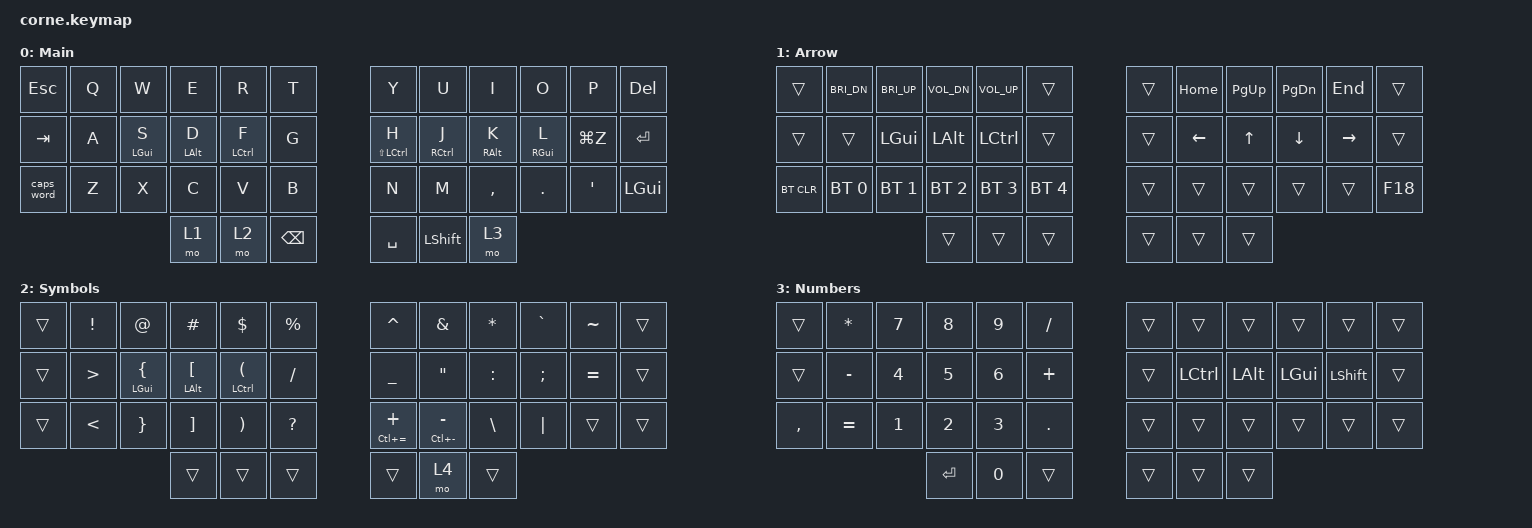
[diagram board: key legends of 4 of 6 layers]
/*
 * Copyright (c) 2020 The ZMK Contributors
 *
 * SPDX-License-Identifier: MIT
 */

#include <behaviors.dtsi>
#include <dt-bindings/zmk/keys.h>
#include <dt-bindings/zmk/bt.h>
#include <dt-bindings/zmk/pointing.h>

// Key positions on the 6-column Corne:
//    0  1  2  3  4  5      6  7  8  9 10 11
//   12 13 14 15 16 17     18 19 20 21 22 23
//   24 25 26 27 28 29     30 31 32 33 34 35
//            36 37 38     39 40 41
#define LEFT_KEYS   0 1 2 3 4 5 12 13 14 15 16 17 24 25 26 27 28 29
#define RIGHT_KEYS  6 7 8 9 10 11 18 19 20 21 22 23 30 31 32 33 34 35
#define THUMB_KEYS  36 37 38 39 40 41

// Fn/Mouse layer, used twice: layer 4 (held with both middle thumbs) and
// layer 5 (the same keys, locked on). Lock Layer = &tog 5: pressing it while
// holding the thumbs locks the layer; pressing it again unlocks.
// Drag Scroll and Navigator CPI +/- belong to the Voyager trackball, so they are empty here.
#define FN_MOUSE_BINDINGS \
   &kp F1  &kp F2  &kp F3         &kp F4     &kp F5     &kp F6    &trans  &msc SCRL_LEFT &msc SCRL_UP  &msc SCRL_DOWN &msc SCRL_RIGHT &trans \
   &trans  &trans  &none          &mkp LCLK  &mkp RCLK  &trans    &trans  &mmv MOVE_LEFT &mmv MOVE_UP  &mmv MOVE_DOWN &mmv MOVE_RIGHT &trans \
   &kp F7  &kp F8  &kp F9         &kp F10    &kp F11    &kp F12   &trans  &tog 5         &none         &none          &trans          &trans \
                   &trans         &trans     &trans               &trans  &trans         &trans

/ {
        behaviors {
                // Home row mods: tap for the letter, hold for the modifier.
                // A hold only counts when the next key is on the other hand or a
                // thumb, so fast typing on one hand doesn't fire modifiers by accident.
                hml: home_row_mod_left {
                        compatible = "zmk,behavior-hold-tap";
                        #binding-cells = <2>;
                        flavor = "balanced";
                        tapping-term-ms = <280>;
                        quick-tap-ms = <175>;
                        require-prior-idle-ms = <150>;
                        bindings = <&kp>, <&kp>;
                        hold-trigger-key-positions = <RIGHT_KEYS THUMB_KEYS>;
                        hold-trigger-on-release;
                };
                hmr: home_row_mod_right {
                        compatible = "zmk,behavior-hold-tap";
                        #binding-cells = <2>;
                        flavor = "balanced";
                        tapping-term-ms = <280>;
                        quick-tap-ms = <175>;
                        require-prior-idle-ms = <150>;
                        bindings = <&kp>, <&kp>;
                        hold-trigger-key-positions = <LEFT_KEYS THUMB_KEYS>;
                        hold-trigger-on-release;
                };
        };

        combos {
                compatible = "zmk,combos";
                // Both inner thumbs (Backspace + Space) pressed together, either
                // order: Shift while held. No idle requirement, because a capital
                // often comes right after a Space.
                shift_combo {
                        timeout-ms = <50>;
                        key-positions = <38 39>;
                        bindings = <&kp LSHFT>;
                };
                // Both middle thumbs (Symbols + Shift) pressed together, either
                // order: Fn/Mouse while held. Pressing any other key ends the wait
                // at once, so the longer window doesn't slow Shift or Symbols.
                mouse_combo {
                        timeout-ms = <100>;
                        key-positions = <37 40>;
                        bindings = <&mo 4>;
                };
        };

        keymap {
                compatible = "zmk,keymap";

                default_layer {
// -----------------------------------------------------------------------------------------
// |  ESC |  Q  |  W  |  E  |  R  |  T  |   |  Y  |  U  |  I  |  O  |  P  | DEL  |
// |  TAB |  A  |S/GUI|D/ALT|F/CTL|  G  |   |H/S+C|J/CTL|K/ALT|L/GUI|SUP+Z| ENT  |
// | CWRD |  Z  |  X  |  C  |  V  |  B  |   |  N  |  M  |  ,  |  .  |  '  | GUI  |
//                    | MO1 | MO2 | BKSP|   | SPC | SFT | MO3 |
// CWRD: Caps Word, capitals until Space or punctuation, then off.
// Shift: hold BKSP and SPC together (see shift_combo).
// Fn/Mouse: hold MO2 and SFT together (see mouse_combo).
                        display-name = "Main";
                        bindings = <
   &kp ESC   &kp Q &kp W           &kp E           &kp R            &kp T   &kp Y                &kp U            &kp I           &kp O           &kp P   &kp DEL
   &kp TAB   &kp A &hml LGUI S     &hml LALT D     &hml LCTRL F     &kp G   &hmr LS(LCTRL) H     &hmr RCTRL J     &hmr RALT K     &hmr RGUI L     &kp LG(Z) &kp RET
   &caps_word &kp Z &kp X          &kp C           &kp V            &kp B   &kp N                &kp M            &kp COMMA       &kp DOT         &kp SQT &kp LGUI
                                   &mo 1           &mo 2            &kp BSPC        &kp SPACE    &kp LSHFT       &mo 3
                        >;
                };
                arrow_layer {
// -----------------------------------------------------------------------------------------
// |      | BRI-| BRI+| VOL-| VOL+|     |   |     | HOME| PGUP| PGDN| END |      |
// |      |     | GUI | ALT | CTRL|     |   |     |  LFT|  UP | DWN | RGT |      |
// | BTCLR| BT1 | BT2 | BT3 | BT4 | BT5 |   |     |     |     |     |     | F18  |
//                    |(held)|     |    |   |     |     |     |
// Blank keys fall through to Main. Bluetooth keys sit on the bottom-left row
// (unused on the Voyager Arrow layer) so pairing can still be switched or cleared.
// F18 (bottom-right): starts and stops Voxtype dictation.
                        display-name = "Arrow";
                        bindings = <
   &trans     &kp C_BRI_DN &kp C_BRI_UP &kp C_VOL_DN &kp C_VOL_UP &trans         &trans   &kp HOME &kp PG_UP &kp PG_DN &kp END   &trans
   &trans     &trans       &kp LGUI     &kp LALT     &kp LCTRL    &trans         &trans   &kp LEFT &kp UP    &kp DOWN  &kp RIGHT &trans
   &bt BT_CLR &bt BT_SEL 0 &bt BT_SEL 1 &bt BT_SEL 2 &bt BT_SEL 3 &bt BT_SEL 4   &trans   &trans   &trans    &trans    &trans    &kp F18
                                        &trans       &trans       &trans         &trans   &trans   &trans
                        >;
                };

                symbols_layer {
// -----------------------------------------------------------------------------------------
// |      |  !  |  @  |  #  |  $  |  %  |   |  ^  |  &  |  *  |  `  |  ~  |      |
// |      |  >  |{/GUI|[/ALT|(/CTL|  /  |   |  _  |  "  |  :  |  ;  |  =  |      |
// |      |  <  |  }  |  ]  |  )  |  ?  |   |+/C+=|-/C+-|  \  |  |  |     |      |
//                    |     |(held)|    |   |     |MOUSE|     |
// MOUSE: right middle thumb opens Fn/Mouse while Symbols is held.
// Blank keys fall through to Main. Holding + or - sends Ctrl+= / Ctrl+- (zoom in / out).
                        display-name = "Symbols";
                        bindings = <
   &trans &kp EXCL &kp AT         &kp HASH       &kp DLLR        &kp PRCNT   &kp CARET          &kp AMPS           &kp STAR  &kp GRAVE &kp TILDE &trans
   &trans &kp GT   &hml LGUI LBRC &hml LALT LBKT &hml LCTRL LPAR &kp FSLH    &kp UNDER          &kp DQT            &kp COLON &kp SEMI  &kp EQUAL &trans
   &trans &kp LT   &kp RBRC       &kp RBKT       &kp RPAR        &kp QMARK   &hmr LC(EQUAL) PLUS &hmr LC(MINUS) MINUS &kp BSLH  &kp PIPE  &trans    &trans
                                  &trans         &trans          &trans      &trans             &mo 4              &trans
                        >;
                };

                numbers_layer {
// -----------------------------------------------------------------------------------------
// |      |  *  |  7  |  8  |  9  |  /  |   |     |     |     |     |     |      |
// |      |  -  |  4  |  5  |  6  |  +  |   |     | CTRL| ALT | GUI | SFT |      |
// |  ,   |  =  |  1  |  2  |  3  |  .  |   |     |     |     |     |     |      |
//                    | ENT |  0  |     |   |     |     |(held)|
// Numpad on the left hand while the right outer thumb holds the layer.
// Right home row: plain modifiers, for shortcuts like Ctrl+1.
// Blank keys fall through to Main (Esc, Tab, Backspace stay where they are).
                        display-name = "Numbers";
                        bindings = <
   &trans    &kp STAR  &kp N7  &kp N8  &kp N9  &kp FSLH    &trans  &trans     &trans    &trans    &trans     &trans
   &trans    &kp MINUS &kp N4  &kp N5  &kp N6  &kp PLUS    &trans  &kp LCTRL  &kp LALT  &kp LGUI  &kp LSHFT  &trans
   &kp COMMA &kp EQUAL &kp N1  &kp N2  &kp N3  &kp DOT     &trans  &trans     &trans    &trans    &trans     &trans
                       &kp RET &kp N0  &trans              &trans  &trans     &trans
                        >;
                };

                fn_mouse_layer {
// -----------------------------------------------------------------------------------------
// |  F1  |  F2 |  F3 |  F4 |  F5 |  F6 |   |     |WH LT|WH UP|WH DN|WH RT|      |
// |      |     |     | LCLK| RCLK|     |   |     |MS LT|MS UP|MS DN|MS RT|      |
// |  F7  |  F8 |  F9 | F10 | F11 | F12 |   |     | LOCK|     |     |     |      |
//                    |     |(held)|     |   |     |(held)|     |
// Reached by holding both middle thumbs (Symbols + Shift) together.
                        display-name = "Fn/Mouse";
                        bindings = <FN_MOUSE_BINDINGS>;
                };

                fn_mouse_locked_layer {
                        display-name = "Fn Lock";
                        bindings = <FN_MOUSE_BINDINGS>;
                };

                extra_1 {
                        status = "reserved";
                };

                extra_2 {
                        status = "reserved";
                };

                extra_3 {
                        status = "reserved";
                };
        };
};
